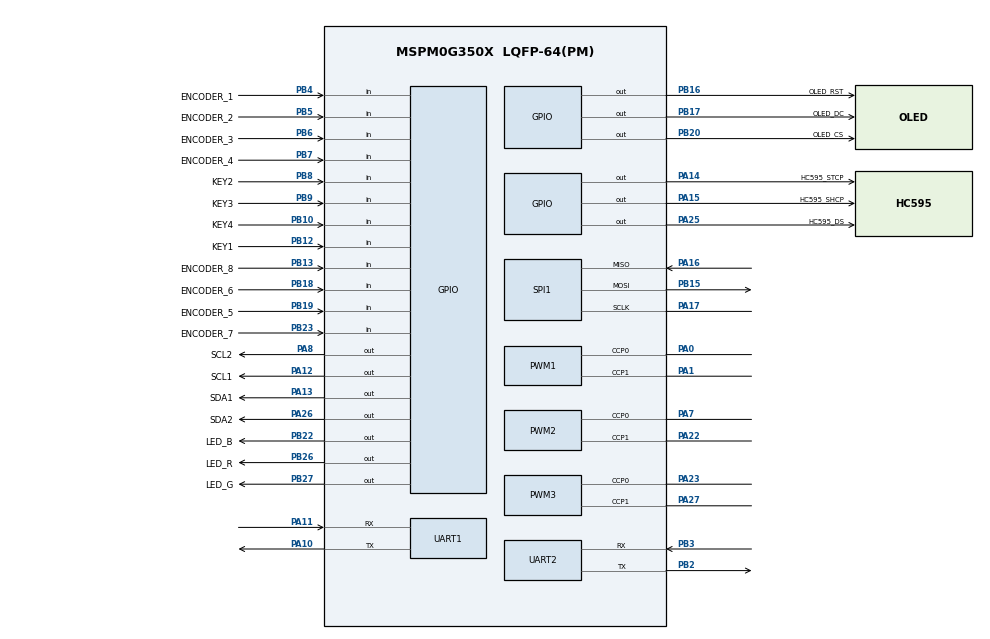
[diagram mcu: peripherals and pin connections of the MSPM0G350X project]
/**
 * @cliArgs --device "MSPM0G350X" --part "Default" --package "LQFP-64(PM)" --product "mspm0_sdk@2.05.01.00"
 * @versions {"tool":"1.24.1+4189"}
 */

/**
 * Import the modules used in this configuration.
 */
const Board         = scripting.addModule("/ti/driverlib/Board");
const GPIO          = scripting.addModule("/ti/driverlib/GPIO", {}, false);
const GPIO1         = GPIO.addInstance();
const GPIO2         = GPIO.addInstance();
const PWM           = scripting.addModule("/ti/driverlib/PWM", {}, false);
const PWM1          = PWM.addInstance();
const PWM2          = PWM.addInstance();
const PWM3          = PWM.addInstance();
const SPI           = scripting.addModule("/ti/driverlib/SPI", {}, false);
const SPI1          = SPI.addInstance();
const SYSCTL        = scripting.addModule("/ti/driverlib/SYSCTL");
const UART          = scripting.addModule("/ti/driverlib/UART", {}, false);
const UART1         = UART.addInstance();
const UART2         = UART.addInstance();
const ProjectConfig = scripting.addModule("/ti/project_config/ProjectConfig");

/**
 * Write custom configuration values to the imported modules.
 */
const divider6       = system.clockTree["PLL_CLK2X_DIV"];
divider6.divideValue = 4;

const divider7       = system.clockTree["PLL_PDIV"];
divider7.divideValue = 2;

const divider9       = system.clockTree["UDIV"];
divider9.divideValue = 2;

const multiplier2         = system.clockTree["PLL_QDIV"];
multiplier2.multiplyValue = 10;

const mux8       = system.clockTree["HSCLKMUX"];
mux8.inputSelect = "HSCLKMUX_SYSPLL2X";


GPIO1.$name                              = "PORTB";
GPIO1.port                               = "PORTB";
GPIO1.associatedPins.create(18);
GPIO1.associatedPins[0].assignedPin      = "26";
GPIO1.associatedPins[0].$name            = "LED_R";
GPIO1.associatedPins[0].pin.$assign      = "PB26";
GPIO1.associatedPins[1].assignedPin      = "27";
GPIO1.associatedPins[1].$name            = "LED_G";
GPIO1.associatedPins[1].pin.$assign      = "PB27";
GPIO1.associatedPins[2].assignedPin      = "22";
GPIO1.associatedPins[2].$name            = "LED_B";
GPIO1.associatedPins[2].pin.$assign      = "PB22";
GPIO1.associatedPins[3].$name            = "OLED_RST";
GPIO1.associatedPins[3].assignedPin      = "16";
GPIO1.associatedPins[3].pin.$assign      = "PB16";
GPIO1.associatedPins[4].$name            = "OLED_DC";
GPIO1.associatedPins[4].assignedPin      = "17";
GPIO1.associatedPins[4].pin.$assign      = "PB17";
GPIO1.associatedPins[5].$name            = "OLED_CS";
GPIO1.associatedPins[5].assignedPin      = "20";
GPIO1.associatedPins[5].pin.$assign      = "PB20";
GPIO1.associatedPins[6].direction        = "INPUT";
GPIO1.associatedPins[6].$name            = "KEY1";
GPIO1.associatedPins[6].assignedPin      = "12";
GPIO1.associatedPins[6].pin.$assign      = "PB12";
GPIO1.associatedPins[7].direction        = "INPUT";
GPIO1.associatedPins[7].$name            = "KEY2";
GPIO1.associatedPins[7].assignedPin      = "8";
GPIO1.associatedPins[7].internalResistor = "PULL_UP";
GPIO1.associatedPins[7].pin.$assign      = "PB8";
GPIO1.associatedPins[8].direction        = "INPUT";
GPIO1.associatedPins[8].$name            = "KEY3";
GPIO1.associatedPins[8].assignedPin      = "9";
GPIO1.associatedPins[8].pin.$assign      = "PB9";
GPIO1.associatedPins[9].direction        = "INPUT";
GPIO1.associatedPins[9].$name            = "KEY4";
GPIO1.associatedPins[9].assignedPin      = "10";
GPIO1.associatedPins[9].pin.$assign      = "PB10";
GPIO1.associatedPins[10].$name           = "ENCODER_1";
GPIO1.associatedPins[10].assignedPin     = "4";
GPIO1.associatedPins[10].direction       = "INPUT";
GPIO1.associatedPins[10].interruptEn     = true;
GPIO1.associatedPins[10].polarity        = "RISE_FALL";
GPIO1.associatedPins[10].pin.$assign     = "PB4";
GPIO1.associatedPins[11].$name           = "ENCODER_2";
GPIO1.associatedPins[11].assignedPin     = "5";
GPIO1.associatedPins[11].direction       = "INPUT";
GPIO1.associatedPins[11].interruptEn     = true;
GPIO1.associatedPins[11].polarity        = "RISE_FALL";
GPIO1.associatedPins[11].pin.$assign     = "PB5";
GPIO1.associatedPins[12].$name           = "ENCODER_3";
GPIO1.associatedPins[12].assignedPin     = "6";
GPIO1.associatedPins[12].direction       = "INPUT";
GPIO1.associatedPins[12].interruptEn     = true;
GPIO1.associatedPins[12].polarity        = "RISE_FALL";
GPIO1.associatedPins[12].pin.$assign     = "PB6";
GPIO1.associatedPins[13].$name           = "ENCODER_4";
GPIO1.associatedPins[13].assignedPin     = "7";
GPIO1.associatedPins[13].direction       = "INPUT";
GPIO1.associatedPins[13].interruptEn     = true;
GPIO1.associatedPins[13].polarity        = "RISE_FALL";
GPIO1.associatedPins[13].pin.$assign     = "PB7";
GPIO1.associatedPins[14].$name           = "ENCODER_5";
GPIO1.associatedPins[14].assignedPin     = "19";
GPIO1.associatedPins[14].direction       = "INPUT";
GPIO1.associatedPins[14].interruptEn     = true;
GPIO1.associatedPins[14].polarity        = "RISE_FALL";
GPIO1.associatedPins[14].pin.$assign     = "PB19";
GPIO1.associatedPins[15].$name           = "ENCODER_6";
GPIO1.associatedPins[15].direction       = "INPUT";
GPIO1.associatedPins[15].polarity        = "RISE_FALL";
GPIO1.associatedPins[15].interruptEn     = true;
GPIO1.associatedPins[15].assignedPin     = "18";
GPIO1.associatedPins[15].pin.$assign     = "PB18";
GPIO1.associatedPins[16].$name           = "ENCODER_7";
GPIO1.associatedPins[16].direction       = "INPUT";
GPIO1.associatedPins[16].interruptEn     = true;
GPIO1.associatedPins[16].polarity        = "RISE_FALL";
GPIO1.associatedPins[16].assignedPin     = "23";
GPIO1.associatedPins[16].pin.$assign     = "PB23";
GPIO1.associatedPins[17].$name           = "ENCODER_8";
GPIO1.associatedPins[17].direction       = "INPUT";
GPIO1.associatedPins[17].interruptEn     = true;
GPIO1.associatedPins[17].polarity        = "RISE_FALL";
GPIO1.associatedPins[17].assignedPin     = "13";
GPIO1.associatedPins[17].pin.$assign     = "PB13";

GPIO2.$name                         = "PORTA";
GPIO2.port                          = "PORTA";
GPIO2.associatedPins.create(7);
GPIO2.associatedPins[0].$name       = "SCL1";
GPIO2.associatedPins[0].pin.$assign = "PA12";
GPIO2.associatedPins[1].$name       = "SDA1";
GPIO2.associatedPins[1].pin.$assign = "PA13";
GPIO2.associatedPins[2].$name       = "SCL2";
GPIO2.associatedPins[2].pin.$assign = "PA8";
GPIO2.associatedPins[3].$name       = "SDA2";
GPIO2.associatedPins[3].pin.$assign = "PA26";
GPIO2.associatedPins[4].$name       = "HC595_DS";
GPIO2.associatedPins[4].pin.$assign = "PA25";
GPIO2.associatedPins[5].$name       = "HC595_SHCP";
GPIO2.associatedPins[5].assignedPin = "15";
GPIO2.associatedPins[5].pin.$assign = "PA15";
GPIO2.associatedPins[6].$name       = "HC595_STCP";
GPIO2.associatedPins[6].pin.$assign = "PA14";

PWM1.$name                              = "Motor_PWM1";
PWM1.timerStartTimer                    = true;
PWM1.pwmMode                            = "EDGE_ALIGN_UP";
PWM1.timerCount                         = 3000;
PWM1.clockDivider                       = 8;
PWM1.peripheral.$assign                 = "TIMA0";
PWM1.peripheral.ccp0Pin.$assign         = "PA0";
PWM1.peripheral.ccp1Pin.$assign         = "PA1";
PWM1.PWM_CHANNEL_0.$name                = "ti_driverlib_pwm_PWMTimerCC0";
PWM1.PWM_CHANNEL_1.$name                = "ti_driverlib_pwm_PWMTimerCC1";
PWM1.ccp0PinConfig.$name                = "ti_driverlib_gpio_GPIOPinGeneric0";
PWM1.ccp0PinConfig.direction            = scripting.forceWrite("OUTPUT");
PWM1.ccp0PinConfig.hideOutputInversion  = scripting.forceWrite(false);
PWM1.ccp0PinConfig.onlyInternalResistor = scripting.forceWrite(false);
PWM1.ccp0PinConfig.passedPeripheralType = scripting.forceWrite("Digital");
PWM1.ccp1PinConfig.$name                = "ti_driverlib_gpio_GPIOPinGeneric1";
PWM1.ccp1PinConfig.direction            = scripting.forceWrite("OUTPUT");
PWM1.ccp1PinConfig.hideOutputInversion  = scripting.forceWrite(false);
PWM1.ccp1PinConfig.onlyInternalResistor = scripting.forceWrite(false);
PWM1.ccp1PinConfig.passedPeripheralType = scripting.forceWrite("Digital");

PWM2.timerCount                         = 3000;
PWM2.clockDivider                       = 8;
PWM2.$name                              = "Motor_PWM2";
PWM2.timerStartTimer                    = true;
PWM2.pwmMode                            = "EDGE_ALIGN_UP";
PWM2.peripheral.$assign                 = "TIMG8";
PWM2.peripheral.ccp0Pin.$assign         = "PA7";
PWM2.peripheral.ccp1Pin.$assign         = "PA22";
PWM2.PWM_CHANNEL_0.$name                = "ti_driverlib_pwm_PWMTimerCC2";
PWM2.PWM_CHANNEL_1.$name                = "ti_driverlib_pwm_PWMTimerCC3";
PWM2.ccp0PinConfig.$name                = "ti_driverlib_gpio_GPIOPinGeneric2";
PWM2.ccp0PinConfig.direction            = scripting.forceWrite("OUTPUT");
PWM2.ccp0PinConfig.hideOutputInversion  = scripting.forceWrite(false);
PWM2.ccp0PinConfig.onlyInternalResistor = scripting.forceWrite(false);
PWM2.ccp0PinConfig.passedPeripheralType = scripting.forceWrite("Digital");
PWM2.ccp1PinConfig.$name                = "ti_driverlib_gpio_GPIOPinGeneric3";
PWM2.ccp1PinConfig.direction            = scripting.forceWrite("OUTPUT");
PWM2.ccp1PinConfig.hideOutputInversion  = scripting.forceWrite(false);
PWM2.ccp1PinConfig.onlyInternalResistor = scripting.forceWrite(false);
PWM2.ccp1PinConfig.passedPeripheralType = scripting.forceWrite("Digital");

PWM3.$name                              = "BEEP_PWM";
PWM3.clockSource                        = "LFCLK";
PWM3.timerStartTimer                    = true;
PWM3.peripheral.$assign                 = "TIMG7";
PWM3.peripheral.ccp0Pin.$assign         = "PA23";
PWM3.peripheral.ccp1Pin.$assign         = "PA27";
PWM3.PWM_CHANNEL_0.$name                = "ti_driverlib_pwm_PWMTimerCC4";
PWM3.PWM_CHANNEL_1.$name                = "ti_driverlib_pwm_PWMTimerCC5";
PWM3.ccp0PinConfig.direction            = scripting.forceWrite("OUTPUT");
PWM3.ccp0PinConfig.hideOutputInversion  = scripting.forceWrite(false);
PWM3.ccp0PinConfig.onlyInternalResistor = scripting.forceWrite(false);
PWM3.ccp0PinConfig.passedPeripheralType = scripting.forceWrite("Digital");
PWM3.ccp0PinConfig.$name                = "ti_driverlib_gpio_GPIOPinGeneric9";
PWM3.ccp1PinConfig.direction            = scripting.forceWrite("OUTPUT");
PWM3.ccp1PinConfig.hideOutputInversion  = scripting.forceWrite(false);
PWM3.ccp1PinConfig.onlyInternalResistor = scripting.forceWrite(false);
PWM3.ccp1PinConfig.passedPeripheralType = scripting.forceWrite("Digital");
PWM3.ccp1PinConfig.$name                = "ti_driverlib_gpio_GPIOPinGeneric10";

SPI1.$name                      = "SPI_0";
SPI1.targetBitRate              = 1000000;
SPI1.frameFormat                = "MOTO3";
SPI1.phase                      = "1";
SPI1.polarity                   = "1";
SPI1.sclkPinConfig.$name        = "ti_driverlib_gpio_GPIOPinGeneric4";
SPI1.mosiPinConfig.$name        = "ti_driverlib_gpio_GPIOPinGeneric5";
SPI1.misoPinConfig.$name        = "ti_driverlib_gpio_GPIOPinGeneric6";
SPI1.peripheral.$assign         = "SPI1";
SPI1.peripheral.sclkPin.$assign = "PA17";
SPI1.peripheral.mosiPin.$assign = "PB15";
SPI1.peripheral.misoPin.$assign = "PA16";

SYSCTL.clockTreeEn = true;
scripting.suppress("For best practices when the CPUCLK is running at 32MHz and above, clear the flash status bit using DL_FlashCTL_executeClearStatus\\(\\) before executing any flash operation\\. Otherwise there may be false positives\\.", SYSCTL);

UART1.$name                    = "UART_0";
UART1.targetBaudRate           = 115200;
UART1.enableFIFO               = true;
UART1.rxFifoThreshold          = "DL_UART_RX_FIFO_LEVEL_ONE_ENTRY";
UART1.txFifoThreshold          = "DL_UART_TX_FIFO_LEVEL_ONE_ENTRY";
UART1.enableDMATX              = false;
UART1.enabledInterrupts        = ["RX"];
UART1.peripheral.$assign       = "UART0";
UART1.peripheral.rxPin.$assign = "PA11";
UART1.peripheral.txPin.$assign = "PA10";
UART1.txPinConfig.$name        = "ti_driverlib_gpio_GPIOPinGeneric7";
UART1.rxPinConfig.$name        = "ti_driverlib_gpio_GPIOPinGeneric8";

UART2.$name                    = "UART_1";
UART2.targetBaudRate           = 115200;
UART2.rxFifoThreshold          = "DL_UART_RX_FIFO_LEVEL_ONE_ENTRY";
UART2.enableDMARX              = false;
UART2.enableDMATX              = false;
UART2.enabledInterrupts        = ["RX"];
UART2.peripheral.$assign       = "UART3";
UART2.peripheral.rxPin.$assign = "PB3";
UART2.peripheral.txPin.$assign = "PB2";
UART2.txPinConfig.$name        = "ti_driverlib_gpio_GPIOPinGeneric11";
UART2.rxPinConfig.$name        = "ti_driverlib_gpio_GPIOPinGeneric12";

ProjectConfig.genDisable = true;
scripting.suppress("Project Configuration File generation is disabled for this project\\. SysConfig Project Migration is not currently supported for this project\\.", ProjectConfig);

/**
 * Pinmux solution for unlocked pins/peripherals. This ensures that minor changes to the automatic solver in a future
 * version of the tool will not impact the pinmux you originally saw.  These lines can be completely deleted in order to
 * re-solve from scratch.
 */
Board.peripheral.$suggestSolution          = "DEBUGSS";
Board.peripheral.swclkPin.$suggestSolution = "PA20";
Board.peripheral.swdioPin.$suggestSolution = "PA19";
